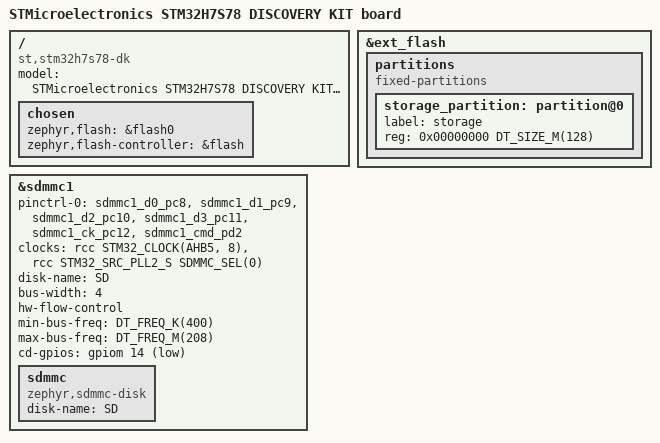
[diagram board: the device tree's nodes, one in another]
/*
 * Copyright (c) 2024-2025 STMicroelectronics
 *
 * SPDX-License-Identifier: Apache-2.0
 */

/dts-v1/;
#include "stm32h7s78_dk-common.dtsi"

/ {
	model = "STMicroelectronics STM32H7S78 DISCOVERY KIT board";
	compatible = "st,stm32h7s78-dk";

	chosen {
		zephyr,flash = &flash0;
		zephyr,flash-controller = &flash;
	};
};

&ext_flash {
	status = "okay";

	partitions {
		compatible = "fixed-partitions";
		#address-cells = <1>;
		#size-cells = <1>;

		storage_partition: partition@0 {
			label = "storage";
			reg = <0x00000000 DT_SIZE_M(128)>; /* 128MB */
		};
	};
};

sdhc: &sdmmc1 {
	pinctrl-0 = <&sdmmc1_d0_pc8 &sdmmc1_d1_pc9
		     &sdmmc1_d2_pc10 &sdmmc1_d3_pc11
		     &sdmmc1_ck_pc12 &sdmmc1_cmd_pd2>;
	clocks = <&rcc STM32_CLOCK(AHB5, 8)>,
		 <&rcc STM32_SRC_PLL2_S SDMMC_SEL(0)>;
	pinctrl-names = "default";
	disk-name = "SD";
	bus-width = <4>;
	hw-flow-control;
	min-bus-freq = <DT_FREQ_K(400)>;
	max-bus-freq = <DT_FREQ_M(208)>;
	cd-gpios = <&gpiom 14 GPIO_ACTIVE_LOW>;

	sdmmc {
		compatible = "zephyr,sdmmc-disk";
		disk-name = "SD";
		status = "okay";
	};
};
